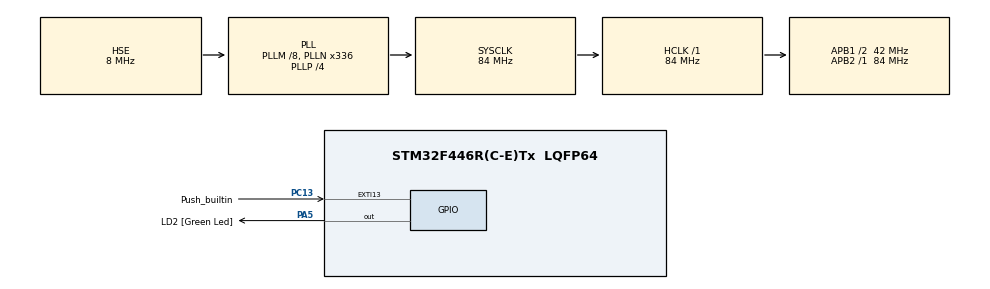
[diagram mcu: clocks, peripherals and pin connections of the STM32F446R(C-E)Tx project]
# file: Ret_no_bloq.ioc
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Mcu.Family=STM32F4
Mcu.Name=STM32F446R(C-E)Tx
Mcu.Package=LQFP64
NVIC.PriorityGroup=NVIC_PRIORITYGROUP_0
PA13.Mode=Serial_Wire
PA13.Signal=SYS_JTMS-SWDIO
PA14.Mode=Serial_Wire
PA14.Signal=SYS_JTCK-SWCLK
PA5.GPIO_Label=LD2 [Green Led]
PA5.Signal=GPIO_Output
PB3.GPIO_Label=SWO
PB3.Signal=SYS_JTDO-SWO
PC13.GPIO_Label=Push_builtin
PC13.GPIO_ModeDefaultEXTI=GPIO_MODE_IT_FALLING
PC13.Signal=GPXTI13
PC14-OSC32_IN.Signal=RCC_OSC32_IN
PC15-OSC32_OUT.Signal=RCC_OSC32_OUT
PH0-OSC_IN.Mode=HSE-External-Clock-Source
PH0-OSC_IN.Signal=RCC_OSC_IN
PH1-OSC_OUT.Mode=HSE-External-Clock-Source
PH1-OSC_OUT.Signal=RCC_OSC_OUT
ProjectManager.HeapSize=0x200
ProjectManager.StackSize=0x400
ProjectManager.TargetToolchain=STM32CubeIDE
RCC.48MHZClocksFreq_Value=84000000
RCC.AHBFreq_Value=84000000
RCC.APB1CLKDivider=RCC_HCLK_DIV2
RCC.APB1Freq_Value=42000000
RCC.APB1TimFreq_Value=84000000
RCC.APB2Freq_Value=84000000
RCC.APB2TimFreq_Value=84000000
RCC.CortexFreq_Value=84000000
RCC.FLatency-AdvancedSettings=FLASH_LATENCY_2
RCC.HCLKFreq_Value=84000000
RCC.HSE_VALUE=8000000
RCC.HSI_VALUE=16000000
RCC.PLLM=8
RCC.PLLN=336
RCC.PLLP=RCC_PLLP_DIV4
RCC.PLLSourceVirtual=RCC_PLLSOURCE_HSE
RCC.SYSCLKFreq_VALUE=84000000
RCC.SYSCLKSource=RCC_SYSCLKSOURCE_PLLCLK
RCC.USBFreq_Value=168000000
RCC.VCOOutputFreq_Value=336000000
board=NUCLEO-F446RE

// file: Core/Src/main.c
/* USER CODE BEGIN Header */
/**
  ******************************************************************************
  * @file           : main.c
  * @brief          : Main program body
  ******************************************************************************
  * @attention
  *
  * Copyright (c) 2026 STMicroelectronics.
  * All rights reserved.
  *
  * This software is licensed under terms that can be found in the LICENSE file
  * in the root directory of this software component.
  * If no LICENSE file comes with this software, it is provided AS-IS.
  *
  ******************************************************************************
  */
/* USER CODE END Header */
#include <API_debounce.h>
#include "main.h"
#include "gpio.h"
#include "blink.h"

/* USER CODE BEGIN Includes */
#include "del.h"
/* USER CODE END Includes */

/* USER CODE BEGIN PD */
#define LED_GREEN 		GPIO_PIN_5
#define LED_GREEN_PORT 	GPIOA
#define PER_A 100			//Frecuencia parpadeo A
#define PER_B 500			//Frecuencia parpadeo B
#define TIME_PUSH 300		//Tiempo de espera nueva lectura push

/* USER CODE END PD */

/* Private variables ---------------------------------------delay------------------*/

void SystemClock_Config(void);

/* USER CODE BEGIN 0 */

delay_t delay;
/* USER CODE END 0 */

int main(void)
{

  /* MCU Configuration--------------------------------------------------------*/

  /* Reset of all peripherals, Initializes the Flash interface and the Systick. */
  HAL_Init();

  /* USER CODE BEGIN Init */
  debounceFSM_init();

  /* USER CODE END Init */

  /* Configure the system clock */
  SystemClock_Config();

  /* Initialize all configured peripherals */
  MX_GPIO_Init();

  /* Infinite loop */
  /* USER CODE BEGIN WHILE */
  st_t state = STATE_LF;			//Sistema inicia en baja frecuencia

  while (1)
  {
    /* USER CODE END WHILE */

    /* USER CODE BEGIN 3 */

	  debounceFSM_update();
	  switch(state){
	  	  case STATE_LF:{
	  		blink(PER_A);			//Parpadeo led Freq A
	  		if(retStat() && ! delayRead(&delay) ){			//Si se presionó el pulsador, y luego de 300 mS
	  			state = STATE_HF;							//Cambio de estado a alta frecuencia
	  			delayWrite(&delay, TIME_PUSH);				//y reseteo el delay del push
	  		};

	  	  }; break;
	  	  case STATE_HF:{
	  		blink(PER_B);			//Parpadeo led Freq B
	  		if(retStat() && ! delayRead(&delay) ){
	  			state = STATE_LF;
	  			delayWrite(&delay, TIME_PUSH);
	  		}
	  	  }; break;
  	  }
	  //debug();
  }

  /* USER CODE END 3 */
}

void SystemClock_Config(void)
{
  RCC_OscInitTypeDef RCC_OscInitStruct = {0};
  RCC_ClkInitTypeDef RCC_ClkInitStruct = {0};

  /** Configure the main internal regulator output voltage
  */
  __HAL_RCC_PWR_CLK_ENABLE();
  __HAL_PWR_VOLTAGESCALING_CONFIG(PWR_REGULATOR_VOLTAGE_SCALE3);

  /** Initializes the RCC Oscillators according to the specified parameters
  * in the RCC_OscInitTypeDef structure.
  */
  RCC_OscInitStruct.OscillatorType = RCC_OSCILLATORTYPE_HSE;
  RCC_OscInitStruct.HSEState = RCC_HSE_BYPASS;
  RCC_OscInitStruct.PLL.PLLState = RCC_PLL_ON;
  RCC_OscInitStruct.PLL.PLLSource = RCC_PLLSOURCE_HSE;
  RCC_OscInitStruct.PLL.PLLM = 8;
  RCC_OscInitStruct.PLL.PLLN = 336;
  RCC_OscInitStruct.PLL.PLLP = RCC_PLLP_DIV4;
  RCC_OscInitStruct.PLL.PLLQ = 2;
  RCC_OscInitStruct.PLL.PLLR = 2;
  if (HAL_RCC_OscConfig(&RCC_OscInitStruct) != HAL_OK)
  {
    Error_Handler();
  }

  /** Initializes the CPU, AHB and APB buses clocks
  */
  RCC_ClkInitStruct.ClockType = RCC_CLOCKTYPE_HCLK|RCC_CLOCKTYPE_SYSCLK
                              |RCC_CLOCKTYPE_PCLK1|RCC_CLOCKTYPE_PCLK2;
  RCC_ClkInitStruct.SYSCLKSource = RCC_SYSCLKSOURCE_PLLCLK;
  RCC_ClkInitStruct.AHBCLKDivider = RCC_SYSCLK_DIV1;
  RCC_ClkInitStruct.APB1CLKDivider = RCC_HCLK_DIV2;
  RCC_ClkInitStruct.APB2CLKDivider = RCC_HCLK_DIV1;

  if (HAL_RCC_ClockConfig(&RCC_ClkInitStruct, FLASH_LATENCY_2) != HAL_OK)
  {
    Error_Handler();
  }
}

void Error_Handler(void)
{
  __disable_irq();
  while (1)
  {
  }
}
